# CH583SFR register map
Vendor: WCH Ltd.; Series: CH58x; File version: 1.1
CPU: RISC-V r0p0, little endian, no MPU, no FPU, 2 interrupt priority bits
Registers are 8-bit, read-write, reset 0x0 unless marked. A register's access mark holds for its fields unless they carry their own. Offsets are from the block's base; [hi:lo] are bit positions.

## UART0
Base 0x40003000
0x00 MCR — RW, UART0 modem control
  [7] MCR_HALF — RW, UART0 enable half-duplex
  [6] MCR_TNOW — RW, UART0 enable TNOW output on DTR pin
  [5] MCR_AU_FLOW_EN — RW, UART0 enable autoflow control
  [4] MCR_LOOP — RW, UART0 enable local loop back
  [3] MCR_OUT2 — RW, UART control OUT2
  [3] MCR_INT_OE — RW, UART interrupt output enable
  [2] MCR_OUT1 — RW, UART0 control OUT1
  [1] MCR_RTS — RW, UART0 control RTS
  [0] MCR_DTR — RW, UART0 control DTR
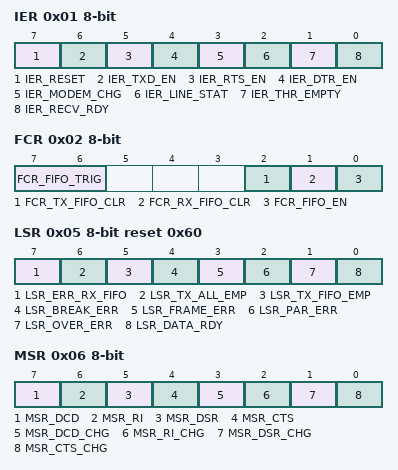
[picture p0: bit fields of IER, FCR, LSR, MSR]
0x01 IER — RW, UART0 interrupt enable
  [7] IER_RESET — WZ, UART software reset control, high action, auto clear
  [6] IER_TXD_EN — RW, UART TXD pin enable
  [5] IER_RTS_EN — RW, UART0 RTS output pin enable
  [4] IER_DTR_EN — RW, UART0 DTR/TNOW output pin enable
  [3] IER_MODEM_CHG — RW, UART0 interrupt enable for modem status change
  [2] IER_LINE_STAT — RW, UART interrupt enable for receiver line status
  [1] IER_THR_EMPTY — RW, UART interrupt enable for THR empty
  [0] IER_RECV_RDY — RW, UART interrupt enable for receiver data ready
0x02 FCR — RW, UART0 FIFO control
  [7:6] FCR_FIFO_TRIG — RW, UART receiver FIFO trigger level: 00-1byte, 01-2bytes, 10-4bytes, 11-7bytes
  [2] FCR_TX_FIFO_CLR — WZ, clear UART transmitter FIFO, high action, auto clear
  [1] FCR_RX_FIFO_CLR — WZ, clear UART receiver FIFO, high action, auto clear
  [0] FCR_FIFO_EN — RW, UART FIFO enable
0x03 LCR — RW, UART0 line control
  [7] LCR_GP_BIT — RW, UART general purpose bit
  [7] LCR_DLAB — RW, UART reserved bit
  [6] LCR_BREAK_EN — RW, UART break control enable
  [5:4] LCR_PAR_MOD — RW, UART parity mode: 00-odd, 01-even, 10-mark, 11-space
  [3] LCR_PAR_EN — RW, UART parity enable
  [2] LCR_STOP_BIT — RW, UART stop bit length: 0-1bit, 1-2bit
  [1:0] LCR_WORD_SZ — RW, UART word bit length: 00-5bit, 01-6bit, 10-7bit, 11-8bit
0x04 IIR ro reset 0x1 — RO, UART0 interrupt identification
  [7:6] IIR_FIFO_ID — RO, UART FIFO enabled flag
  [0] IIR_NO_INT — RO, UART no interrupt flag: 0=interrupt action, 1=no interrupt
  [3:0] IIR_INT_MASK — RO, UART interrupt flag bit mask
0x05 LSR ro reset 0x60 — RO, UART0 line status
  [7] LSR_ERR_RX_FIFO — RO, indicate error in UART receiver fifo
  [6] LSR_TX_ALL_EMP — RO, UART transmitter all empty status
  [5] LSR_TX_FIFO_EMP — RO, UART transmitter fifo empty status
  [4] LSR_BREAK_ERR — RZ, UART receiver break error
  [3] LSR_FRAME_ERR — RZ, UART receiver frame error
  [2] LSR_PAR_ERR — RZ, UART receiver parity error
  [1] LSR_OVER_ERR — RZ, UART receiver overrun error
  [0] LSR_DATA_RDY — RO, UART receiver fifo data ready status
0x06 MSR ro — RO, UART0 modem status
  [7] MSR_DCD — RO, UART0 DCD action status
  [6] MSR_RI — RO, UART0 RI action status
  [5] MSR_DSR — RO, UART0 DSR action statusv
  [4] MSR_CTS — RO, UART0 CTS action status
  [3] MSR_DCD_CHG — RZ, UART0 DCD changed status, high action
  [2] MSR_RI_CHG — RZ, UART0 RI changed status, high action
  [1] MSR_DSR_CHG — RZ, UART0 DSR changed status, high action
  [0] MSR_CTS_CHG — RZ, UART0 CTS changed status, high action
0x08 RBR ro — RO, UART0 receiver buffer, receiving byte
0x08 THR wo — WO, UART0 transmitter holding, transmittal byte
  [7:0] THR — RO, UART0 transmitter holding, transmittal byte
0x0A RFC ro — RO, UART0 receiver FIFO count
0x0B TFC ro — RO, UART0 transmitter FIFO count
0x0C DL 16-bit — RW, UART0 divisor latch
0x0E DIV — RW, UART0 pre-divisor latch byte, only low 7 bit, from 1 to 0/128
  [7:0] DIV — RW,UART0 pre-divisor latch byte, only low 7 bit, from 1 to 0/128
0x0F ADR reset 0xFF — RW, UART0 slave address: 0xFF=disable, other=enable
  [7:0] ADR — RW,UART0 slave address: 0xFF=disable, other=enable

## UART1
Base 0x40003400
Registers as UART0 (with UART0 read as UART1), without MSR, ADR; these are added or differ:
0x00 MCR — RW, UART1 modem control
  [3] MCR_OUT2 — RW, UART control OUT2
  [3] MCR_INT_OE — RW, UART interrupt output enable
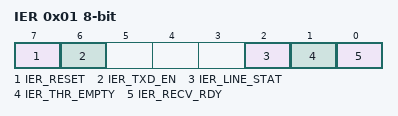
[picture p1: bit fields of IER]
0x01 IER — RW, UART1 interrupt enable
  [7] IER_RESET — WZ, UART software reset control, high action, auto clear
  [6] IER_TXD_EN — RW, UART TXD pin enable
  [2] IER_LINE_STAT — RW, UART interrupt enable for receiver line status
  [1] IER_THR_EMPTY — RW, UART interrupt enable for THR empty
  [0] IER_RECV_RDY — RW, UART interrupt enable for receiver data ready
0x04 IIR ro reset 0x1 — RO, UART1 interrupt identification
  [7] IIR_FIFO_ID — RO, UART FIFO enabled flag
  [0] IIR_NO_INT — RO, UART no interrupt flag: 0=interrupt action, 1=no interrupt
  [3:0] IIR_INT_MASK — RO, UART interrupt flag bit mask
0x08 THR wo — WO, UART1 transmitter holding, transmittal byte
  [7:0] RBR
0x0B TFC ro — RO, UART1 transmitter FIFO count
  [7:0] TFC — RO, UART1 receiver FIFO count
0x0E DIV — RW, UART1 pre-divisor latch byte, only low 7 bit, from 1 to 128

## UART2
Base 0x40003800
Registers as UART1 (with UART1 read as UART2); these are added or differ:
0x08 THR wo — WO, UART2 transmitter holding, transmittal byte
0x0B TFC ro — RO, UART2 transmitter FIFO count

## UART3
Base 0x40003C00
Registers as UART2 (with UART2 read as UART3); these are added or differ:
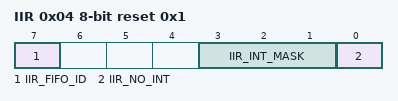
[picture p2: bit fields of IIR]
0x04 IIR ro reset 0x1 — RO, UART3 interrupt identification
  [7] IIR_FIFO_ID — RO, UART FIFO enabled flag
  [3:1] IIR_INT_MASK — RO, UART interrupt flag bit mask
  [0] IIR_NO_INT — RO, UART no interrupt flag: 0=interrupt action, 1=no interrupt
